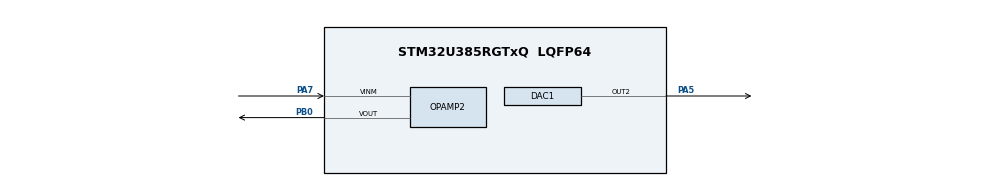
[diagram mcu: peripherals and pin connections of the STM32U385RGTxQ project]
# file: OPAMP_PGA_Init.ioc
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CORTEX_M33_NS.userName=CORTEX_M33
DAC1.DAC_Channel-DAC_OUT2_ExtAndInt=DAC_CHANNEL_2
Mcu.Family=STM32U3
Mcu.Name=STM32U385RGTxQ
Mcu.Package=LQFP64
NVIC.PriorityGroup=NVIC_PRIORITYGROUP_4
PA5.Signal=COMP_DAC12_group
PA7.Mode=PGA Connected-DAC_OUT2-INP
PA7.Signal=OPAMP2_VINM
PB0.Mode=PGA Connected-DAC_OUT2-INP
PB0.Signal=OPAMP2_VOUT
ProjectManager.HeapSize=0x200
ProjectManager.StackSize=0x400
ProjectManager.TargetToolchain=STM32CubeIDE
RCC.ADCFreq_Value=96000000
RCC.AHBFreq_Value=96000000
RCC.APB1Freq_Value=96000000
RCC.APB1TimFreq_Value=96000000
RCC.APB2Freq_Value=96000000
RCC.APB2TimFreq_Value=96000000
RCC.APB3Freq_Value=96000000
RCC.CortexFreq_Value=12000000
RCC.HCLKFreq_Value=96000000
RCC.HSE_VALUE=16000000
RCC.HSI48_VALUE=48000000
RCC.HSI_VALUE=16000000
RCC.LSE_VALUE=32768
RCC.LSIDIV_VALUE=32000
RCC.MSISDIV=RCC_MSI_DIV1
RCC.SYSCLKFreq_VALUE=96000000
RCC.USBFreq_Value=96000000
SH.COMP_DAC12_group.0=DAC1_OUT2,DAC_OUT2_ExtAndInt
VP_ICACHE_VS_ICACHE.Mode=DirectMappedCache
VP_PWR_VS_DBSignals.Mode=DisableDeadBatterySignals
VP_PWR_VS_LPOM.Mode=PowerOptimisation
VP_PWR_VS_SECSignals.Mode=Security/Privilege
board=custom

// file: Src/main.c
/* USER CODE BEGIN Header */
/**
  ******************************************************************************
  * @file    Examples_LL/OPAMP/OPAMP_PGA_Init/Src/main.c
  * @author  MCD Application Team
  * @brief   This example describes how to use the OPAMP PGA mode.
  *          This example is based on the STM32U3xx OPAMP LL API;
  *          Peripheral initialization done using LL unitary services functions.
  ******************************************************************************
  * @attention
  *
  * Copyright (c) 2024 STMicroelectronics.
  * All rights reserved.
  *
  * This software is licensed under terms that can be found in the LICENSE file
  * in the root directory of this software component.
  * If no LICENSE file comes with this software, it is provided AS-IS.
  *
  ******************************************************************************
  */
/* USER CODE END Header */
#include "main.h"

/* USER CODE BEGIN PD */
/* Definitions of environment analog values */
  /* Value of analog reference voltage (Vref+), connected to analog voltage   */
  /* supply Vdda (unit: mV).                                                  */
  #define VDDA_APPLI                       ((uint32_t)3300)

/* Definitions of data related to this example */
  /* Full-scale digital value with a resolution of 12 bits (voltage range     */
  /* determined by analog voltage references Vref+ and Vref-,                 */
  /* refer to reference manual).                                              */
  #define DIGITAL_SCALE_12BITS             (__LL_DAC_DIGITAL_SCALE(LL_DAC_RESOLUTION_12B))

/* USER CODE END PD */

/* USER CODE BEGIN PV */
__IO uint8_t ubButtonPress = 0;
__IO uint8_t ubButtonPressCount = 0;

/* USER CODE END PV */

void SystemClock_Config(void);
static void MX_GPIO_Init(void);
static void MX_DAC1_Init(void);
static void MX_OPAMP2_Init(void);
static void MX_ICACHE_Init(void);
/* USER CODE BEGIN PFP */
void     Activate_COMP(void);
void     Activate_DAC(void);
void     Activate_OPAMP(void);
void     LED_On(void);
void     LED_Off(void);
/* USER CODE END PFP */

int main(void)
{

  /* MCU Configuration--------------------------------------------------------*/

  /* Reset of all peripherals, Initializes the Flash interface and the Systick. */

  /* System interrupt init*/
  NVIC_SetPriorityGrouping(NVIC_PRIORITYGROUP_4);

  /* SysTick_IRQn interrupt configuration */
  NVIC_SetPriority(SysTick_IRQn, NVIC_EncodePriority(NVIC_GetPriorityGrouping(),15, 0));

  /* Configure the system clock */
  SystemClock_Config();

  /* Initialize all configured peripherals */
  MX_GPIO_Init();
  MX_DAC1_Init();
  MX_OPAMP2_Init();
  MX_ICACHE_Init();
  /* USER CODE BEGIN 2 */

  /* Activate DAC channel */
  Activate_DAC();

  /* Activate OPAMP */
  Activate_OPAMP();

  /* USER CODE END 2 */

  /* Infinite loop */
  while (1)
  {

  }
}

void SystemClock_Config(void)
{
  /** Enable Epod Booster
  */
  LL_AHB1_GRP2_EnableClock(LL_AHB1_GRP2_PERIPH_PWR);
  LL_RCC_SetEPODBoosterClkSource(LL_RCC_EPODBOOSTCLKSRCE_MSIS);
  LL_RCC_SetEPODBoosterClkPrescaler(LL_RCC_EPODBOOSTCLKPRESCAL_1);
  LL_PWR_EnableEPODBooster();
  while(LL_PWR_IsActiveFlag_BOOST() != 1U)
  {
  }

  /** Configure the main internal regulator output voltage
  */
  LL_PWR_SetRegulVoltageScaling(LL_PWR_REGU_VOLTAGE_SCALE1);
  while(LL_PWR_GetRegulCurrentVOS() != LL_PWR_REGU_VOLTAGE_SCALE1)
  {
  }

  /** Set Flash latency before switching to MSIS
  */
  LL_FLASH_SetLatency(LL_FLASH_LATENCY_2);
  while(LL_FLASH_GetLatency() != LL_FLASH_LATENCY_2)
  {
  }

  LL_PWR_EnableBkUpAccess();
  while (LL_PWR_IsEnabledBkUpAccess () == 0U)
  {
  }

  LL_RCC_LSI_Enable();

   /* Wait till LSI is ready */
  while(LL_RCC_LSI_IsReady() != 1)
  {
  }

  /* Activate MSIS as source */
  LL_RCC_MSIS_SetClockSource(LL_RCC_MSIS_CLOCK_SOURCE_RC0);
  LL_RCC_MSIS_SetClockDivision(LL_RCC_MSIS_CLOCK_SOURCE_RC_DIV_1);
  LL_RCC_MSI_SetMSIxClockRange();
  LL_RCC_SetSysClkSource(LL_RCC_SYS_CLKSOURCE_MSIS);

   /* Wait till System clock is ready */
  while(LL_RCC_GetSysClkSource() != LL_RCC_SYS_CLKSOURCE_MSIS)
  {
  }

  LL_RCC_SetAHBPrescaler(LL_RCC_HCLK_SYSCLK_DIV_1);
  LL_RCC_SetAPB1Prescaler(LL_RCC_APB1_HCLK_DIV_1);
  LL_RCC_SetAPB2Prescaler(LL_RCC_APB2_HCLK_DIV_1);
  LL_RCC_SetAPB3Prescaler(LL_RCC_APB3_HCLK_DIV_1);

  LL_Init1msTick(96000000);

  LL_SetSystemCoreClock(96000000);
}

static void MX_DAC1_Init(void)
{

  LL_DAC_InitTypeDef DAC_InitStruct = {0};

  LL_GPIO_InitTypeDef GPIO_InitStruct = {0};

  LL_RCC_SetADCDACClockSource(LL_RCC_ADCDAC_CLKSOURCE_HCLK);
  LL_RCC_SetDACSHClockSource(LL_RCC_DAC1SH_CLKSOURCE_LSI);

  /* Peripheral clock enable */
  LL_AHB2_GRP1_EnableClock(LL_AHB2_GRP1_PERIPH_DAC1);

  LL_AHB2_GRP1_EnableClock(LL_AHB2_GRP1_PERIPH_GPIOA);
  /**DAC1 GPIO Configuration
  PA5   ------> DAC1_OUT2
  */
  GPIO_InitStruct.Pin = LL_GPIO_PIN_5;
  GPIO_InitStruct.Mode = LL_GPIO_MODE_ANALOG;
  GPIO_InitStruct.Pull = LL_GPIO_PULL_NO;
  LL_GPIO_Init(GPIOA, &GPIO_InitStruct);

  /** Common Parameters
  */
  LL_DAC_DisableAutonomousMode(DAC1);
  LL_DAC_SetHighFrequencyMode(DAC1, LL_DAC_HIGH_FREQ_MODE_DISABLE);

  /** DAC channel OUT2 config
  */
  LL_DAC_SetSignedFormat(DAC1, LL_DAC_CHANNEL_2, LL_DAC_SIGNED_FORMAT_DISABLE);
  DAC_InitStruct.TriggerSource = LL_DAC_TRIG_SOFTWARE;
  DAC_InitStruct.WaveAutoGeneration = LL_DAC_WAVE_AUTO_GENERATION_NONE;
  DAC_InitStruct.OutputConnection = LL_DAC_OUTPUT_CONNECT_INTERNAL;
  DAC_InitStruct.OutputMode = LL_DAC_OUTPUT_MODE_NORMAL;
  LL_DAC_Init(DAC1, LL_DAC_CHANNEL_2, &DAC_InitStruct);
  LL_DAC_DisableTrigger(DAC1, LL_DAC_CHANNEL_2);
  LL_DAC_DisableDMADoubleDataMode(DAC1, LL_DAC_CHANNEL_2);

}

static void MX_ICACHE_Init(void)
{

  /** Enable instruction cache in 1-way (direct mapped cache)
  */
  LL_ICACHE_SetMode(LL_ICACHE_1WAY);
  LL_ICACHE_Enable();

}

static void MX_OPAMP2_Init(void)
{

  LL_OPAMP_InitTypeDef OPAMP_InitStruct = {0};

  LL_GPIO_InitTypeDef GPIO_InitStruct = {0};

  /* Peripheral clock enable */
  LL_APB1_GRP1_EnableClock(LL_APB1_GRP1_PERIPH_OPAMP);

  LL_AHB2_GRP1_EnableClock(LL_AHB2_GRP1_PERIPH_GPIOA);
  LL_AHB2_GRP1_EnableClock(LL_AHB2_GRP1_PERIPH_GPIOB);
  /**OPAMP2 GPIO Configuration
  PA7   ------> OPAMP2_VINM
  PB0   ------> OPAMP2_VOUT
  */
  GPIO_InitStruct.Pin = LL_GPIO_PIN_7;
  GPIO_InitStruct.Mode = LL_GPIO_MODE_ANALOG;
  GPIO_InitStruct.Pull = LL_GPIO_PULL_NO;
  LL_GPIO_Init(GPIOA, &GPIO_InitStruct);

  GPIO_InitStruct.Pin = LL_GPIO_PIN_0;
  GPIO_InitStruct.Mode = LL_GPIO_MODE_ANALOG;
  GPIO_InitStruct.Pull = LL_GPIO_PULL_NO;
  LL_GPIO_Init(GPIOB, &GPIO_InitStruct);

  OPAMP_InitStruct.PowerMode = LL_OPAMP_POWERMODE_NORMALPOWER_NORMALSPEED;
  OPAMP_InitStruct.FunctionalMode = LL_OPAMP_MODE_PGA;
  OPAMP_InitStruct.InputNonInverting = LL_OPAMP_INPUT_NONINVERT_DAC;
  OPAMP_InitStruct.InputInverting = LL_OPAMP_INPUT_INVERT_IO0;
  LL_OPAMP_Init(OPAMP2, &OPAMP_InitStruct);
  LL_OPAMP_SetPGAGain(OPAMP2, LL_OPAMP_PGA_GAIN_2);
  LL_OPAMP_SetTrimmingMode(OPAMP2, LL_OPAMP_TRIMMING_FACTORY);

}

static void MX_GPIO_Init(void)
{

  /* GPIO Ports Clock Enable */
  LL_AHB2_GRP1_EnableClock(LL_AHB2_GRP1_PERIPH_GPIOA);
  LL_AHB2_GRP1_EnableClock(LL_AHB2_GRP1_PERIPH_GPIOB);

}

/* USER CODE BEGIN 4 */

/**
  * @brief  Perform DAC activation procedure to make it ready to generate
  *         a voltage (DAC instance: DAC1).
  * @note   Operations:
  *         - Enable DAC instance channel
  *         - Wait for DAC instance channel startup time
  * @param  None
  * @retval None
  */
void Activate_DAC(void)
{
  __IO uint32_t wait_loop_index = 0;

  /* Enable DAC channel */
  LL_DAC_Enable(DAC1, LL_DAC_CHANNEL_2);

  /* Delay for DAC channel voltage settling time from DAC channel startup.    */
  /* Compute number of CPU cycles to wait for, from delay in us.              */
  /* Note: Variable divided by 2 to compensate partially                      */
  /*       CPU processing cycles (depends on compilation optimization).       */
  /* Note: If system core clock frequency is below 200kHz, wait time          */
  /*       is only a few CPU processing cycles.                               */
  wait_loop_index = ((LL_DAC_DELAY_STARTUP_VOLTAGE_SETTLING_US * (SystemCoreClock / (100000 * 2))) / 10);
  while(wait_loop_index != 0)
  {
    wait_loop_index--;
  }

  /* Enable DAC channel trigger */
  /* Note: DAC channel conversion can start from trigger enable:              */
  /*       - if DAC channel trigger source is set to SW:                      */
  /*         DAC channel conversion will start after trig order               */
  /*         using function "LL_DAC_TrigSWConversion()".                      */
  /*       - if DAC channel trigger source is set to external trigger         */
  /*         (timer, ...):                                                    */
  /*         DAC channel conversion can start immediately                     */
  /*         (after next trig order from external trigger)                    */
  LL_DAC_EnableTrigger(DAC1, LL_DAC_CHANNEL_2);

  /* Set data to be loaded in data holding register */
  LL_DAC_ConvertData12RightAligned(DAC1, LL_DAC_CHANNEL_2, __LL_DAC_CALC_VOLTAGE_TO_DATA(VDDA_APPLI, (VDDA_APPLI/4), LL_DAC_RESOLUTION_12B));

  /* Trig DAC conversion by software */
  LL_DAC_TrigSWConversion(DAC1, LL_DAC_CHANNEL_2);
}

/**
  * @brief  Perform OPAMP activation procedure
  *         (OPAMP instance: OPAMP2).
  * @note   Operations:
  *         - Enable OPAMP instance
  *         - Wait for OPAMP startup time
  * @param  None
  * @retval None
  */
void Activate_OPAMP(void)
{
  __IO uint32_t wait_loop_index = 0;

  /* Enable OPAMP */
  LL_OPAMP_Enable(OPAMP2);

  /* Delay for OPAMP startup time.                                            */
  /* Compute number of CPU cycles to wait for, from delay in us.              */
  /* Note: Variable divided by 2 to compensate partially                      */
  /*       CPU processing cycles (depends on compilation optimization).       */
  /* Note: If system core clock frequency is below 200kHz, wait time          */
  /*       is only a few CPU processing cycles.                               */
  wait_loop_index = ((LL_OPAMP_DELAY_STARTUP_US * (SystemCoreClock / (100000 * 2))) / 10);
  while(wait_loop_index != 0)
  {
    wait_loop_index--;
  }

}
/**
  * @brief  Turn-on LD2.
  * @param  None
  * @retval None
  */
void LED_On(void)
{
  /* Turn LD2 on */
  LL_GPIO_SetOutputPin(LD2_GPIO_Port, LD2_Pin);
}

/**
  * @brief  Turn-off LD2.
  * @param  None
  * @retval None
  */
void LED_Off(void)
{
  /* Turn LD2 off */
  LL_GPIO_ResetOutputPin(LD2_GPIO_Port, LD2_Pin);
}

/* USER CODE END 4 */

void Error_Handler(void)
{
}
